# AT91SAM9M10 register map
Vendor: Atmel; File version: 20130207
CPU: 
Registers are 32-bit, read-write, no defined reset value unless marked. A register's access mark holds for its fields unless they carry their own. Offsets are from the block's base; [hi:lo] are bit positions; {n}, {i} and the like mark numbered series.

## MATRIX — AHB Bus Matrix
Base 0xFFFFEA00; register names take the prefix MATRIX_
{0x0+4i} MCFG[{i}] (i=0..10) — Master Configuration Register
  [2:0] ULBT — Undefined Length Burst Type
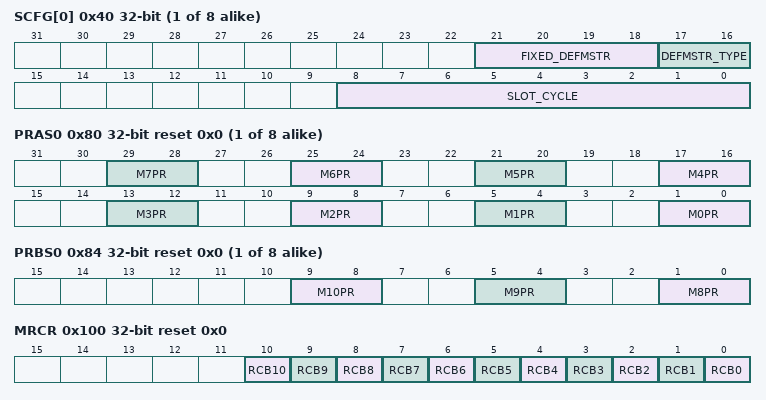
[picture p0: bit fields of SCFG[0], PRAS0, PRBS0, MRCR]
{0x40+4i} SCFG[{i}] (i=0..7) — Slave Configuration Register
  [21:18] FIXED_DEFMSTR — Fixed Default Master
  [17:16] DEFMSTR_TYPE — Default Master Type
  [8:0] SLOT_CYCLE — Maximum Bus Grant Duration for Masters
{0x80+8i} PRAS{i} reset 0x0 (i=0..7) — Priority Register A for Slave {i}
  [4n+1:4n] M{n}PR (n=0..7) — Master {n} Priority
{0x84+8i} PRBS{i} reset 0x0 (i=0..7) — Priority Register B for Slave {i}
  [9:8] M10PR — Master 10 Priority
  [5:4] M9PR — Master 9 Priority
  [1:0] M8PR — Master 8 Priority
0x100 MRCR reset 0x0 — Master Remap Control Register
  [n] RCB{n} (n=0..10)
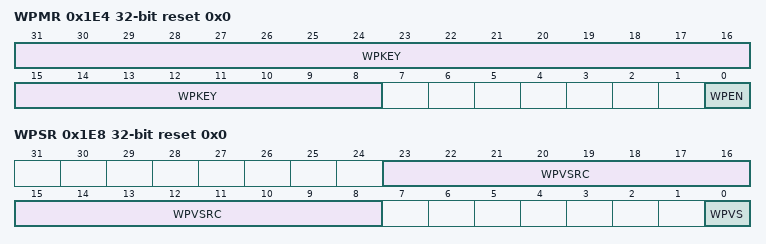
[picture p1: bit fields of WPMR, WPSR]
0x1E4 WPMR reset 0x0 — Write Protect Mode Register
  [31:8] WPKEY — Write Protect KEY (Write-only)
  [0] WPEN — Write Protect ENable
0x1E8 WPSR ro reset 0x0 — Write Protect Status Register
  [23:8] WPVSRC — Write Protect Violation Source
  [0] WPVS — Write Protect Violation Status

## AIC — Advanced Interrupt Controller
Base 0xFFFFF000; register names take the prefix AIC_
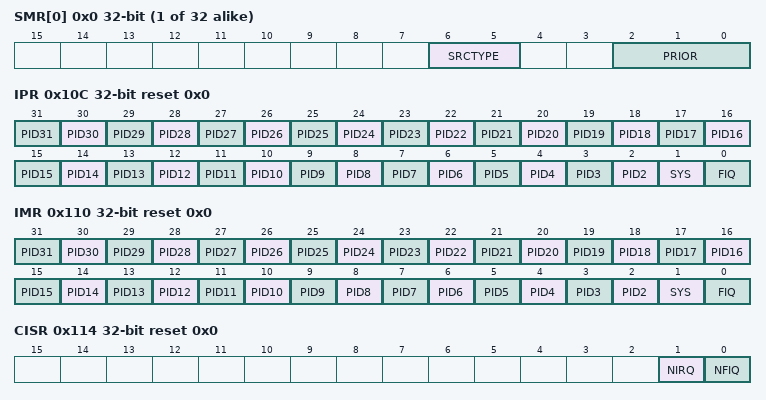
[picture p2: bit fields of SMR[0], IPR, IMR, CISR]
{0x0+4i} SMR[{i}] (i=0..31) — Source Mode Register
  [6:5] SRCTYPE — Interrupt Source Type
  [2:0] PRIOR — Priority Level
{0x80+4i} SVR[{i}] (i=0..31) — Source Vector Register
  [31:0] VECTOR — Source Vector
0x100 IVR ro reset 0x0 — Interrupt Vector Register
  [31:0] IRQV
0x104 FVR ro reset 0x0 — FIQ Interrupt Vector Register
  [31:0] FIQV — FIQ Vector Register
0x108 ISR ro reset 0x0 — Interrupt Status Register
  [4:0] IRQID — Current Interrupt Identifier
0x10C IPR ro reset 0x0 — Interrupt Pending Register
  [n] PID{n} (n=2..31) — Interrupt Pending
  [1] SYS — Interrupt Pending
  [0] FIQ — Interrupt Pending
0x110 IMR ro reset 0x0 — Interrupt Mask Register
  [n] PID{n} (n=2..31) — Interrupt Mask
  [1] SYS — Interrupt Mask
  [0] FIQ — Interrupt Mask
0x114 CISR ro reset 0x0 — Core Interrupt Status Register
  [1] NIRQ — NIRQ Status
  [0] NFIQ — NFIQ Status
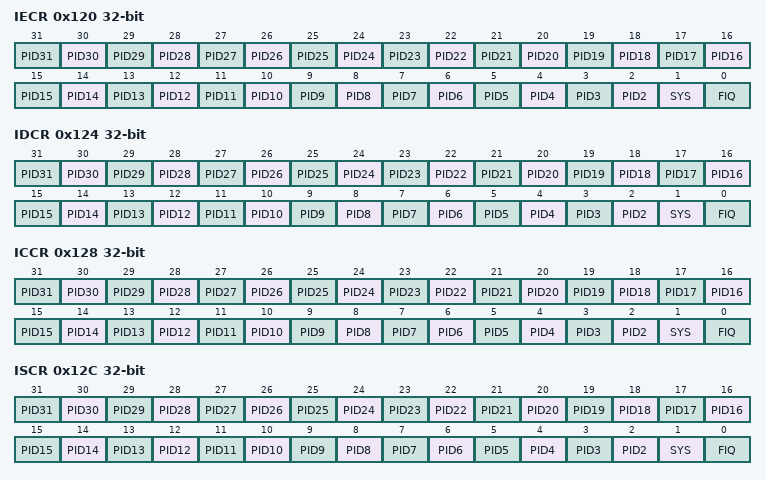
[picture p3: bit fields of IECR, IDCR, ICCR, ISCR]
0x120 IECR wo — Interrupt Enable Command Register
  [n] PID{n} (n=2..31) — Interrupt Enable
  [1] SYS — Interrupt Enable
  [0] FIQ — Interrupt Enable
0x124 IDCR wo — Interrupt Disable Command Register
  [n] PID{n} (n=2..31) — Interrupt Disable
  [1] SYS — Interrupt Disable
  [0] FIQ — Interrupt Disable
0x128 ICCR wo — Interrupt Clear Command Register
  [n] PID{n} (n=2..31) — Interrupt Clear
  [1] SYS — Interrupt Clear
  [0] FIQ — Interrupt Clear
0x12C ISCR wo — Interrupt Set Command Register
  [n] PID{n} (n=2..31) — Interrupt Set
  [1] SYS — Interrupt Set
  [0] FIQ — Interrupt Set
0x130 EOICR wo — End of Interrupt Command Register
0x134 SPU reset 0x0 — Spurious Interrupt Vector Register
  [31:0] SIVR
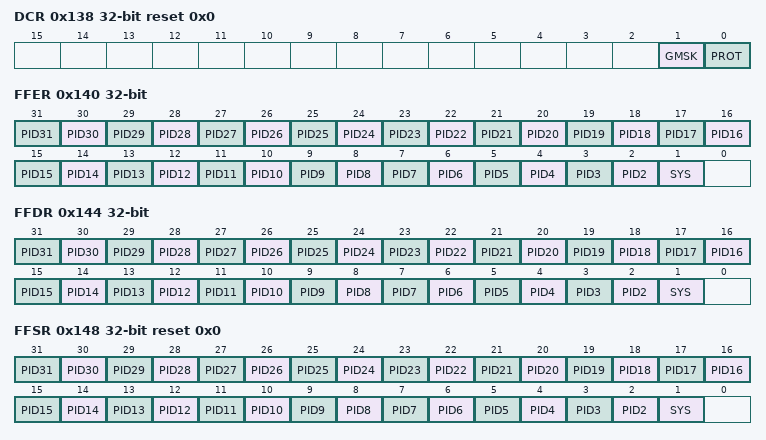
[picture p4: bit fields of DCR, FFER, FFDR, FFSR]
0x138 DCR reset 0x0 — Debug Control Register
  [1] GMSK — General Mask
  [0] PROT — Protection Mode
0x140 FFER wo — Fast Forcing Enable Register
  [n] PID{n} (n=2..31) — Fast Forcing Enable
  [1] SYS — Fast Forcing Enable
0x144 FFDR wo — Fast Forcing Disable Register
  [n] PID{n} (n=2..31) — Fast Forcing Disable
  [1] SYS — Fast Forcing Disable
0x148 FFSR ro reset 0x0 — Fast Forcing Status Register
  [n] PID{n} (n=2..31) — Fast Forcing Status
  [1] SYS — Fast Forcing Status

## PIOA — Parallel Input/Output Controller A
Base 0xFFFFF200; register names take the prefix PIOA_
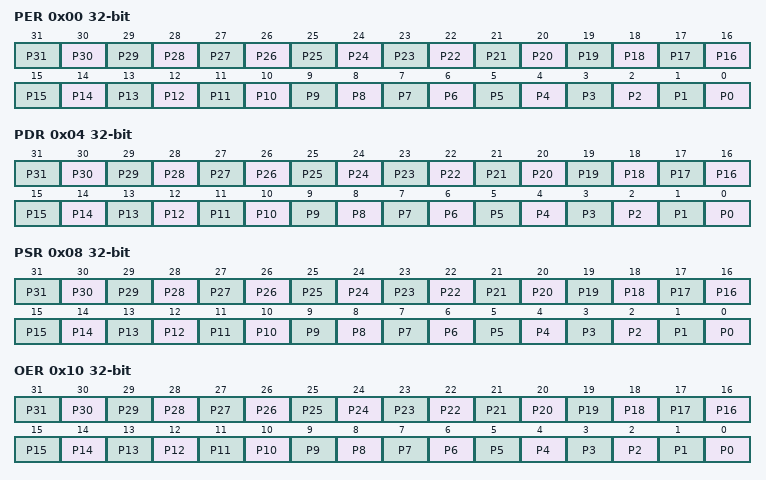
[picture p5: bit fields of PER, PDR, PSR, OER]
0x00 PER wo — PIO Enable Register
  [n] P{n} (n=0..31) — PIO Enable
0x04 PDR wo — PIO Disable Register
  [n] P{n} (n=0..31) — PIO Disable
0x08 PSR ro — PIO Status Register
  [n] P{n} (n=0..31) — PIO Status
0x10 OER wo — Output Enable Register
  [n] P{n} (n=0..31) — Output Enable
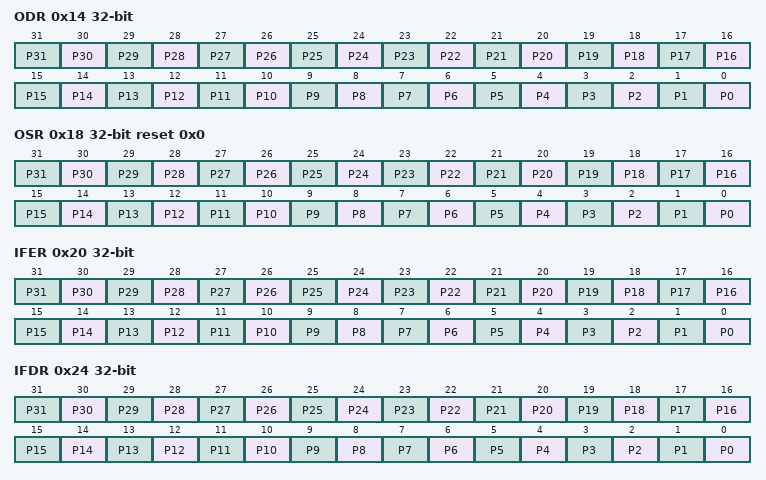
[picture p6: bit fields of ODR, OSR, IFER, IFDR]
0x14 ODR wo — Output Disable Register
  [n] P{n} (n=0..31) — Output Disable
0x18 OSR ro reset 0x0 — Output Status Register
  [n] P{n} (n=0..31) — Output Status
0x20 IFER wo — Glitch Input Filter Enable Register
  [n] P{n} (n=0..31) — Input Filter Enable
0x24 IFDR wo — Glitch Input Filter Disable Register
  [n] P{n} (n=0..31) — Input Filter Disable
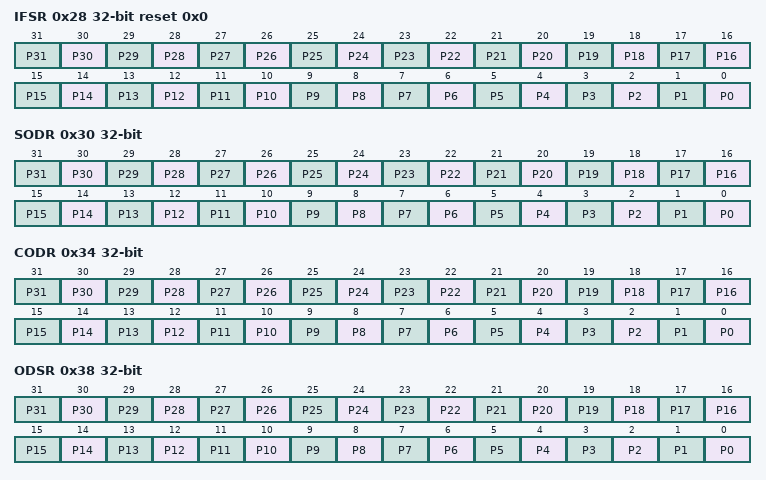
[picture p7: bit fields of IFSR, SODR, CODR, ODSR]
0x28 IFSR ro reset 0x0 — Glitch Input Filter Status Register
  [n] P{n} (n=0..31) — Input Filer Status
0x30 SODR wo — Set Output Data Register
  [n] P{n} (n=0..31) — Set Output Data
0x34 CODR wo — Clear Output Data Register
  [n] P{n} (n=0..31) — Clear Output Data
0x38 ODSR — Output Data Status Register
  [n] P{n} (n=0..31) — Output Data Status
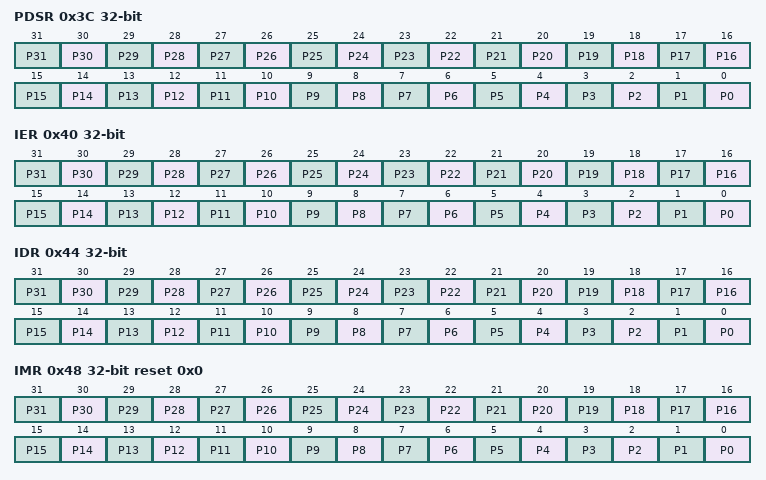
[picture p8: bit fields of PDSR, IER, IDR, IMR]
0x3C PDSR ro — Pin Data Status Register
  [n] P{n} (n=0..31) — Output Data Status
0x40 IER wo — Interrupt Enable Register
  [n] P{n} (n=0..31) — Input Change Interrupt Enable
0x44 IDR wo — Interrupt Disable Register
  [n] P{n} (n=0..31) — Input Change Interrupt Disable
0x48 IMR ro reset 0x0 — Interrupt Mask Register
  [n] P{n} (n=0..31) — Input Change Interrupt Mask
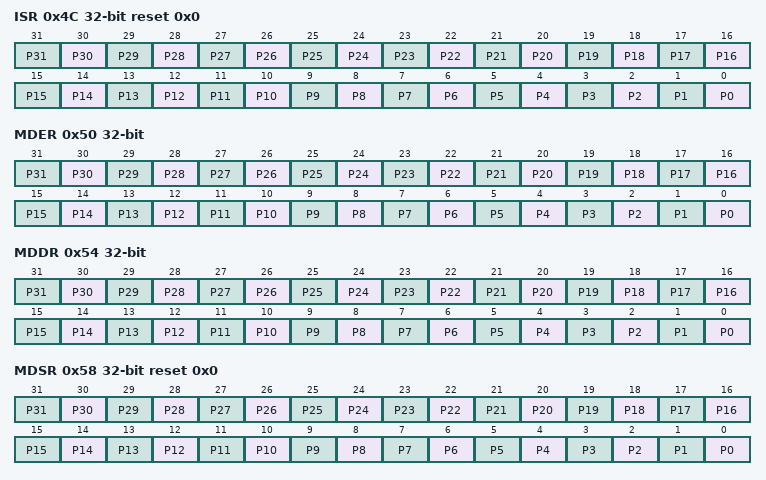
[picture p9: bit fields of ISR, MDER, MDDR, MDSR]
0x4C ISR ro reset 0x0 — Interrupt Status Register
  [n] P{n} (n=0..31) — Input Change Interrupt Status
0x50 MDER wo — Multi-driver Enable Register
  [n] P{n} (n=0..31) — Multi Drive Enable.
0x54 MDDR wo — Multi-driver Disable Register
  [n] P{n} (n=0..31) — Multi Drive Disable.
0x58 MDSR ro reset 0x0 — Multi-driver Status Register
  [n] P{n} (n=0..31) — Multi Drive Status.
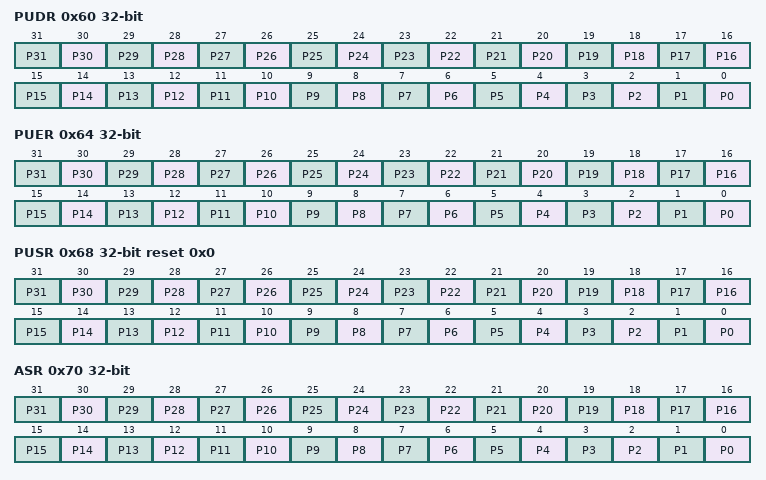
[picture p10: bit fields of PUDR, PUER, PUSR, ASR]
0x60 PUDR wo — Pull-up Disable Register
  [n] P{n} (n=0..31) — Pull Up Disable.
0x64 PUER wo — Pull-up Enable Register
  [n] P{n} (n=0..31) — Pull Up Enable.
0x68 PUSR ro reset 0x0 — Pad Pull-up Status Register
  [n] P{n} (n=0..31) — Pull Up Status.
0x70 ASR wo — Peripheral A Select Register
  [n] P{n} (n=0..31) — Peripheral A Select.
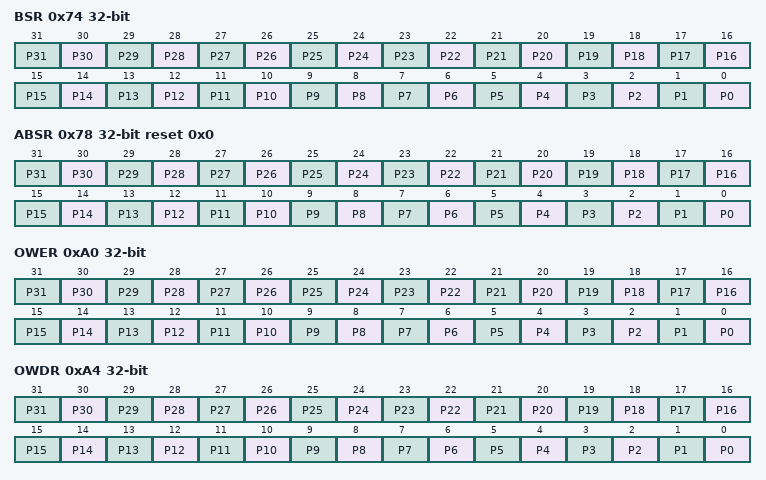
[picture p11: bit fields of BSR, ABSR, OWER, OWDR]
0x74 BSR wo — Peripheral B Select Register
  [n] P{n} (n=0..31) — Peripheral B Select.
0x78 ABSR ro reset 0x0 — AB Status Register
  [n] P{n} (n=0..31) — Peripheral A B Status.
0xA0 OWER wo — Output Write Enable
  [n] P{n} (n=0..31) — Output Write Enable.
0xA4 OWDR wo — Output Write Disable
  [n] P{n} (n=0..31) — Output Write Disable.
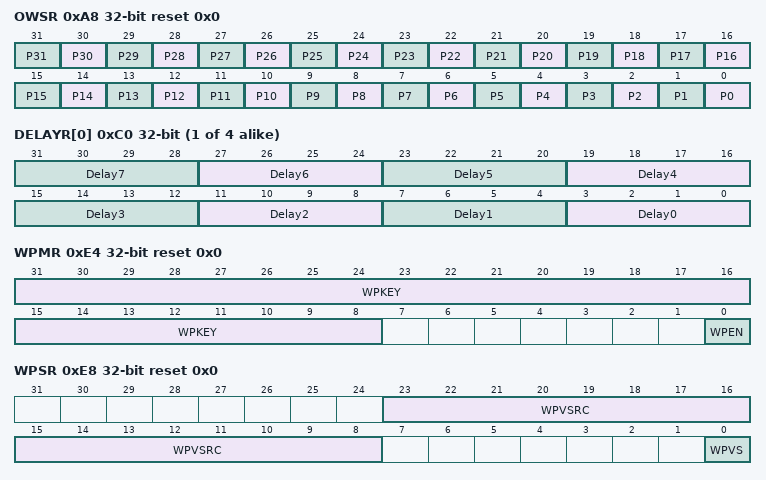
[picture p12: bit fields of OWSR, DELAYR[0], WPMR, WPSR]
0xA8 OWSR ro reset 0x0 — Output Write Status Register
  [n] P{n} (n=0..31) — Output Write Status.
{0xC0+4i} DELAYR[{i}] (i=0..3) — I/O Delay Register
  [4n+3:4n] Delay{n} (n=0..7)
0xE4 WPMR reset 0x0 — Write Protect Mode Register
  [31:8] WPKEY — Write Protect KEY
  [0] WPEN — Write Protect Enable
0xE8 WPSR ro reset 0x0 — Write Protect Status Register
  [23:8] WPVSRC — Write Protect Violation Source
  [0] WPVS — Write Protect Enable

## PIOB — Parallel Input/Output Controller B
Base 0xFFFFF400; register names take the prefix PIOB_
Registers as PIOA.

## PIOC — Parallel Input/Output Controller C
Base 0xFFFFF600; register names take the prefix PIOC_
Registers as PIOA.

## PIOD — Parallel Input/Output Controller D
Base 0xFFFFF800; register names take the prefix PIOD_
Registers as PIOA.

## PIOE — Parallel Input/Output Controller E
Base 0xFFFFFA00; register names take the prefix PIOE_
Registers as PIOA.
